# G32R502 register map
Vendor: Geehy Semiconductor Co., Ltd.; Series: G32R5; File version: 1.0
CPU: CM52 r0p1, little endian, MPU, FPU, DSP, VTOR, 4 interrupt priority bits
Registers are 32-bit, read-write, reset 0x0 unless marked. A register's access mark holds for its fields unless they carry their own. Offsets are from the block's base; [hi:lo] are bit positions; {n}, {i} and the like mark numbered series.

## INPUTXBAR
Base 0x40030C00
0x00 INPUT1SELECT 16-bit reset 0xFFFE — INPUT1 Input Select Register
  [15:0] SELECT — Select GPIO for INPUT1 signal
0x02 INPUT2SELECT 16-bit reset 0xFFFE — INPUT2 Input Select Register
  [15:0] SELECT — Select GPIO for INPUT2 signal
0x04 INPUT3SELECT 16-bit reset 0xFFFE — INPUT3 Input Select Register
  [15:0] SELECT — Select GPIO for INPUT3 signal
0x06 INPUT4SELECT 16-bit reset 0xFFFE — INPUT4 Input Select Register
  [15:0] SELECT — Select GPIO for INPUT4 signal
0x08 INPUT5SELECT 16-bit reset 0xFFFE — INPUT5 Input Select Register
  [15:0] SELECT — Select GPIO for INPUT5 signal
0x0A INPUT6SELECT 16-bit reset 0xFFFE — INPUT6 Input Select Register
  [15:0] SELECT — Select GPIO for INPUT6 signal
0x0C INPUT7SELECT 16-bit reset 0xFFFE — INPUT7 Input Select Register
  [15:0] SELECT — Select GPIO for INPUT7 signal
0x0E INPUT8SELECT 16-bit reset 0xFFFE — INPUT8 Input Select Register
  [15:0] SELECT — Select GPIO for INPUT8 signal
0x10 INPUT9SELECT 16-bit reset 0xFFFE — INPUT9 Input Select Register
  [15:0] SELECT — Select GPIO for INPUT9 signal
0x12 INPUT10SELECT 16-bit reset 0xFFFE — INPUT10 Input Select Register
  [15:0] SELECT — Select GPIO for INPUT10 signal
0x14 INPUT11SELECT 16-bit reset 0xFFFE — INPUT11 Input Select Register
  [15:0] SELECT — Select GPIO for INPUT11 signal
0x16 INPUT12SELECT 16-bit reset 0xFFFE — INPUT12 Input Select Register
  [15:0] SELECT — Select GPIO for INPUT12 signal
0x18 INPUT13SELECT 16-bit reset 0xFFFE — INPUT13 Input Select Register
  [15:0] SELECT — Select GPIO for INPUT13 signal
0x1A INPUT14SELECT 16-bit reset 0xFFFE — INPUT14 Input Select Register
  [15:0] SELECT — Select GPIO for INPUT14 signal
0x1C INPUT15SELECT 16-bit reset 0xFFFE — INPUT15 Input Select Register
  [15:0] SELECT — Select GPIO for INPUT15 signal
0x1E INPUT16SELECT 16-bit reset 0xFFFE — INPUT16 Input Select Register
  [15:0] SELECT — Select GPIO for INPUT16 signal
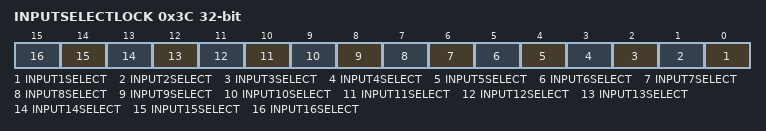
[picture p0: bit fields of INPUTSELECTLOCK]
0x3C INPUTSELECTLOCK rw-once
  [n-1] INPUT{n}SELECT (n=1..16) — Lock bit for INPUT{n}SELECT Register

## XBAR — Crossbar
Base 0x40031000
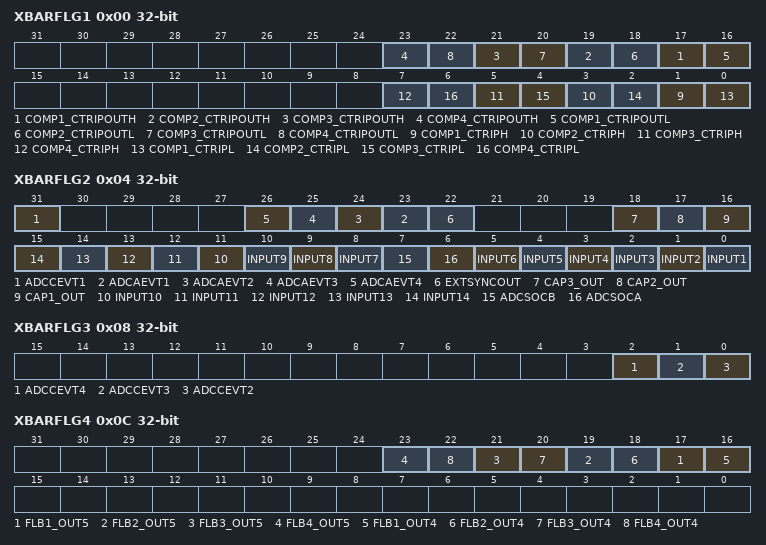
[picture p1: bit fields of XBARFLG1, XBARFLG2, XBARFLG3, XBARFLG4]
0x00 XBARFLG1 ro — X-Bar Input Flag Register 1
  [2n+15] COMP{n}_CTRIPOUTH (n=1..4) — Input Flag for COMP{n}.CTRIPOUTH Signal
  [2n+14] COMP{n}_CTRIPOUTL (n=1..4) — Input Flag for COMP{n}.CTRIPOUTL Signal
  [2n-1] COMP{n}_CTRIPH (n=1..4) — Input Flag for COMP{n}.CTRIPH Signal
  [2n-2] COMP{n}_CTRIPL (n=1..4) — Input Flag for COMP{n}.CTRIPL Signal
0x04 XBARFLG2 ro — X-Bar Input Flag Register 2
  [31] ADCCEVT1 — Input Flag for ADCCEVT1 Signal
  [n+22] ADCAEVT{n} (n=1..4) — Input Flag for ADCAEVT{n} Signal
  [22] EXTSYNCOUT — Input Flag for EXTSYNCOUT Signal
  [18] CAP3_OUT — Input Flag for CAP3.OUT Signal
  [17] CAP2_OUT — Input Flag for CAP2.OUT Signal
  [16] CAP1_OUT — Input Flag for CAP1.OUT Signal
  [n+1] INPUT{n} (n=7..14) — Input Flag for INPUT{n} Signal
  [7] ADCSOCB — Input Flag for ADCSOCB Signal
  [6] ADCSOCA — Input Flag for ADCSOCA Signal
  [n-1] INPUT{n} (n=1..6) — Input Flag for INPUT{n} Signal
0x08 XBARFLG3 ro — X-Bar Input Flag Register 3
  [2] ADCCEVT4 — Input Flag for ADCCEVT4 Signal
  [1] ADCCEVT3 — Input Flag for ADCCEVT3 Signal
  [0] ADCCEVT2 — Input Flag for ADCCEVT2 Signal
0x0C XBARFLG4 ro — X-Bar Input Flag Register 4
  [2n+15] FLB{n}_OUT5 (n=1..4) — Input Flag for FLB{n}_OUT5 Signal
  [2n+14] FLB{n}_OUT4 (n=1..4) — Input Flag for FLB{n}_OUT4 Signal
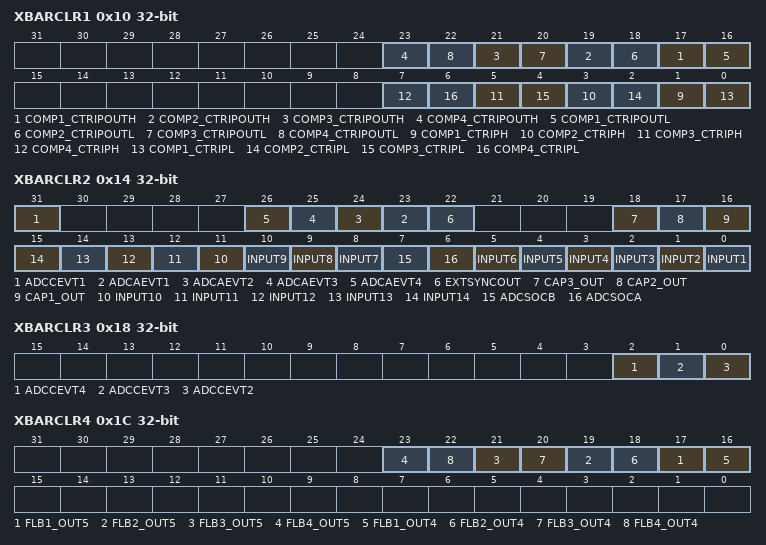
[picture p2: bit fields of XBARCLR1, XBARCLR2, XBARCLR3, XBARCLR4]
0x10 XBARCLR1 — X-Bar Input Flag Clear Register 1
  [2n+15] COMP{n}_CTRIPOUTH (n=1..4) — Input Flag Clear for COMP{n}.CTRIPOUTH Signal
  [2n+14] COMP{n}_CTRIPOUTL (n=1..4) — Input Flag Clear for COMP{n}.CTRIPOUTL Signal
  [2n-1] COMP{n}_CTRIPH (n=1..4) — Input Flag Clear for COMP{n}.CTRIPH Signal
  [2n-2] COMP{n}_CTRIPL (n=1..4) — Input Flag Clear for COMP{n}.CTRIPL Signal
0x14 XBARCLR2 — X-Bar Input Flag Clear Register 2
  [31] ADCCEVT1 — Input Flag Clear for ADCCEVT1 Signal
  [n+22] ADCAEVT{n} (n=1..4) — Input Flag Clear for ADCAEVT{n} Signal
  [22] EXTSYNCOUT — Input Flag Clear for EXTSYNCOUT Signal
  [18] CAP3_OUT — Input Flag Clear for CAP3.OUT Signal
  [17] CAP2_OUT — Input Flag Clear for CAP2.OUT Signal
  [16] CAP1_OUT — Input Flag Clear for CAP1.OUT Signal
  [n+1] INPUT{n} (n=7..14) — Input Signal for INPUT{n} Signal
  [7] ADCSOCB — Input Flag Clear for ADCSOCB Signal
  [6] ADCSOCA — Input Flag Clear for ADCSOCA Signal
  [n-1] INPUT{n} (n=1..6) — Input Signal for INPUT{n} Signal
0x18 XBARCLR3 — X-Bar Input Flag Clear Register 3
  [2] ADCCEVT4 — Input Flag Clear for ADCCEVT4 Signal
  [1] ADCCEVT3 — Input Flag Clear for ADCCEVT3 Signal
  [0] ADCCEVT2 — Input Flag Clear for ADCCEVT2 Signal
0x1C XBARCLR4 — X-Bar Input Flag Clear Register 4
  [2n+15] FLB{n}_OUT5 (n=1..4) — Input Flag clear for FLB{n}_OUT5 Signal
  [2n+14] FLB{n}_OUT4 (n=1..4) — Input Flag clear for FLB{n}_OUT4 Signal
